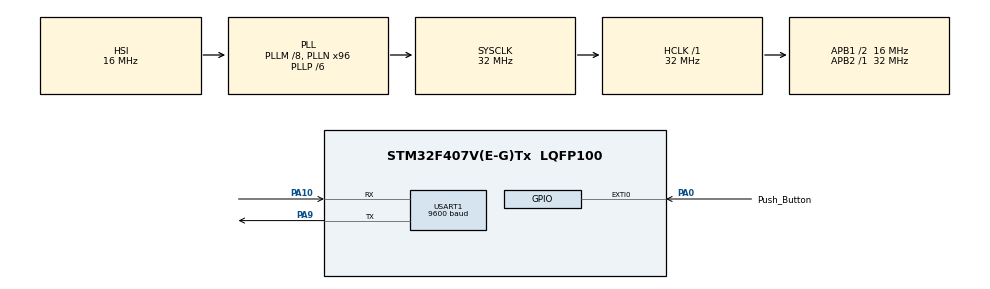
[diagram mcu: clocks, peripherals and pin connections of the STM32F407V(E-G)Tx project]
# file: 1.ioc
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Mcu.Family=STM32F4
Mcu.Name=STM32F407V(E-G)Tx
Mcu.Package=LQFP100
NVIC.EXTI0_IRQn=true\:0\:0\:false\:false\:true\:true\:true
NVIC.PriorityGroup=NVIC_PRIORITYGROUP_4
NVIC.TIM1_BRK_TIM9_IRQn=true\:0\:0\:false\:false\:true\:true\:true
NVIC.TIM1_CC_IRQn=true\:0\:0\:false\:false\:true\:true\:true
NVIC.TIM1_TRG_COM_TIM11_IRQn=true\:0\:0\:false\:false\:true\:true\:true
NVIC.TIM1_UP_TIM10_IRQn=true\:0\:0\:false\:false\:true\:true\:true
PA0-WKUP.GPIO_Label=Push_Button
PA0-WKUP.Signal=GPXTI0
PA10.Mode=Asynchronous
PA10.Signal=USART1_RX
PA9.Mode=Asynchronous
PA9.Signal=USART1_TX
ProjectManager.HeapSize=0x200
ProjectManager.StackSize=0x400
ProjectManager.TargetToolchain=TrueSTUDIO
RCC.48MHZClocksFreq_Value=48000000
RCC.AHBFreq_Value=32000000
RCC.APB1CLKDivider=RCC_HCLK_DIV2
RCC.APB1Freq_Value=16000000
RCC.APB1TimFreq_Value=32000000
RCC.APB2Freq_Value=32000000
RCC.APB2TimFreq_Value=32000000
RCC.CortexFreq_Value=32000000
RCC.HCLKFreq_Value=32000000
RCC.HSE_VALUE=25000000
RCC.HSI_VALUE=16000000
RCC.LSE_VALUE=32768
RCC.PLLM=8
RCC.PLLN=96
RCC.PLLP=RCC_PLLP_DIV6
RCC.SYSCLKFreq_VALUE=32000000
RCC.SYSCLKSource=RCC_SYSCLKSOURCE_PLLCLK
RCC.VCOOutputFreq_Value=192000000
TIM1.Period=100
TIM1.Prescaler=32000
USART1.BaudRate=9600
USART1.Mode=MODE_TX
USART1.VirtualMode=VM_ASYNC
VP_TIM1_VS_ClockSourceINT.Mode=Internal
board=custom

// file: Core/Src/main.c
/* USER CODE BEGIN Header */
/**
  ******************************************************************************
  * @file           : main.c
  * @brief          : Main program body
  ******************************************************************************
  * @attention
  *
  * <h2><center>&copy; Copyright (c) 2021 STMicroelectronics.
  * All rights reserved.</center></h2>
  *
  * This software component is licensed by ST under BSD 3-Clause license,
  * the "License"; You may not use this file except in compliance with the
  * License. You may obtain a copy of the License at:
  *                        opensource.org/licenses/BSD-3-Clause
  *
  ******************************************************************************
  */
/* USER CODE END Header */
#include "main.h"

/* USER CODE BEGIN Includes */
#include <string.h>
/* USER CODE END Includes */

TIM_HandleTypeDef htim1;

UART_HandleTypeDef huart1;

void SystemClock_Config(void);
static void MX_GPIO_Init(void);
static void MX_USART1_UART_Init(void);
static void MX_TIM1_Init(void);

int main(void)
{

  /* MCU Configuration--------------------------------------------------------*/

  /* Reset of all peripherals, Initializes the Flash interface and the Systick. */
  HAL_Init();

  /* Configure the system clock */
  SystemClock_Config();

  /* Initialize all configured peripherals */
  MX_GPIO_Init();
  MX_USART1_UART_Init();
  MX_TIM1_Init();

  /* Infinite loop */
  while (1)
  {

  }
}

void SystemClock_Config(void)
{
  RCC_OscInitTypeDef RCC_OscInitStruct = {0};
  RCC_ClkInitTypeDef RCC_ClkInitStruct = {0};

  /** Configure the main internal regulator output voltage
  */
  __HAL_RCC_PWR_CLK_ENABLE();
  __HAL_PWR_VOLTAGESCALING_CONFIG(PWR_REGULATOR_VOLTAGE_SCALE1);
  /** Initializes the RCC Oscillators according to the specified parameters
  * in the RCC_OscInitTypeDef structure.
  */
  RCC_OscInitStruct.OscillatorType = RCC_OSCILLATORTYPE_HSI;
  RCC_OscInitStruct.HSIState = RCC_HSI_ON;
  RCC_OscInitStruct.HSICalibrationValue = RCC_HSICALIBRATION_DEFAULT;
  RCC_OscInitStruct.PLL.PLLState = RCC_PLL_ON;
  RCC_OscInitStruct.PLL.PLLSource = RCC_PLLSOURCE_HSI;
  RCC_OscInitStruct.PLL.PLLM = 8;
  RCC_OscInitStruct.PLL.PLLN = 96;
  RCC_OscInitStruct.PLL.PLLP = RCC_PLLP_DIV6;
  RCC_OscInitStruct.PLL.PLLQ = 4;
  if (HAL_RCC_OscConfig(&RCC_OscInitStruct) != HAL_OK)
  {
    Error_Handler();
  }
  /** Initializes the CPU, AHB and APB buses clocks
  */
  RCC_ClkInitStruct.ClockType = RCC_CLOCKTYPE_HCLK|RCC_CLOCKTYPE_SYSCLK
                              |RCC_CLOCKTYPE_PCLK1|RCC_CLOCKTYPE_PCLK2;
  RCC_ClkInitStruct.SYSCLKSource = RCC_SYSCLKSOURCE_PLLCLK;
  RCC_ClkInitStruct.AHBCLKDivider = RCC_SYSCLK_DIV1;
  RCC_ClkInitStruct.APB1CLKDivider = RCC_HCLK_DIV2;
  RCC_ClkInitStruct.APB2CLKDivider = RCC_HCLK_DIV1;

  if (HAL_RCC_ClockConfig(&RCC_ClkInitStruct, FLASH_LATENCY_1) != HAL_OK)
  {
    Error_Handler();
  }
}

static void MX_TIM1_Init(void)
{

  TIM_ClockConfigTypeDef sClockSourceConfig = {0};
  TIM_MasterConfigTypeDef sMasterConfig = {0};

  htim1.Instance = TIM1;
  htim1.Init.Prescaler = 32000;
  htim1.Init.CounterMode = TIM_COUNTERMODE_UP;
  htim1.Init.Period = 100;
  htim1.Init.ClockDivision = TIM_CLOCKDIVISION_DIV1;
  htim1.Init.RepetitionCounter = 0;
  htim1.Init.AutoReloadPreload = TIM_AUTORELOAD_PRELOAD_DISABLE;
  if (HAL_TIM_Base_Init(&htim1) != HAL_OK)
  {
    Error_Handler();
  }
  sClockSourceConfig.ClockSource = TIM_CLOCKSOURCE_INTERNAL;
  if (HAL_TIM_ConfigClockSource(&htim1, &sClockSourceConfig) != HAL_OK)
  {
    Error_Handler();
  }
  sMasterConfig.MasterOutputTrigger = TIM_TRGO_RESET;
  sMasterConfig.MasterSlaveMode = TIM_MASTERSLAVEMODE_DISABLE;
  if (HAL_TIMEx_MasterConfigSynchronization(&htim1, &sMasterConfig) != HAL_OK)
  {
    Error_Handler();
  }

}

static void MX_USART1_UART_Init(void)
{

  huart1.Instance = USART1;
  huart1.Init.BaudRate = 9600;
  huart1.Init.WordLength = UART_WORDLENGTH_8B;
  huart1.Init.StopBits = UART_STOPBITS_1;
  huart1.Init.Parity = UART_PARITY_NONE;
  huart1.Init.Mode = UART_MODE_TX;
  huart1.Init.HwFlowCtl = UART_HWCONTROL_NONE;
  huart1.Init.OverSampling = UART_OVERSAMPLING_16;
  if (HAL_UART_Init(&huart1) != HAL_OK)
  {
    Error_Handler();
  }

}

static void MX_GPIO_Init(void)
{
  GPIO_InitTypeDef GPIO_InitStruct = {0};

  /* GPIO Ports Clock Enable */
  __HAL_RCC_GPIOA_CLK_ENABLE();

  /*Configure GPIO pin : Push_Button_Pin */
  GPIO_InitStruct.Pin = Push_Button_Pin;
  GPIO_InitStruct.Mode = GPIO_MODE_IT_RISING;
  GPIO_InitStruct.Pull = GPIO_NOPULL;
  HAL_GPIO_Init(Push_Button_GPIO_Port, &GPIO_InitStruct);

  /* EXTI interrupt init*/
  HAL_NVIC_SetPriority(EXTI0_IRQn, 0, 0);
  HAL_NVIC_EnableIRQ(EXTI0_IRQn);

}

/* USER CODE BEGIN 4 */
void HAL_GPIO_EXTI_Callback(uint16_t GPIO_Pin)
{
	TIM_HandleTypeDef *htim;
	htim = &htim1;
	if(GPIO_Pin == Push_Button_Pin && htim->State == HAL_TIM_STATE_READY){ //start timer if only button is pressed and timer is ready
		HAL_TIM_Base_Start_IT(&htim1);
	}
}

void HAL_TIM_PeriodElapsedCallback(TIM_HandleTypeDef *htim)
{
  /* Prevent unused argument(s) compilation warning */
  UNUSED(htim);

  /* NOTE : This function should not be modified, when the callback is needed,
            the HAL_TIM_PeriodElapsedCallback could be implemented in the user file
   */

  //We only need to check for unpressed button
  if(HAL_GPIO_ReadPin(Push_Button_GPIO_Port, Push_Button_Pin) == GPIO_PIN_SET){ //Button not pressed, transmit data (if > 1 s) and turn off the timer
	  if (__HAL_TIM_GET_COUNTER(htim) - 1 > 10) {// We transmit only values greater than 1s.
		  uint16_t seconds;
		  char buffer[10];
		  seconds = (uint16_t) (__HAL_TIM_GET_COUNTER(htim) - 1 )/ 10; //as timer triggers every 100 ms we should divide counter 10
		  snprintf(buffer, "%dsec\n", seconds);
		  HAL_UART_Transmit(&huart1, (uint8_t *)buffer, sizeof(buffer), 15); //We take 15ms to transmit data as for BaudRate = 9600 byte is transmitted for 1024 us. We have up to 10 bytes - its <11ms.
	  }
	  HAL_TIM_Base_Stop_IT(&htim1);
  }

}
/* USER CODE END 4 */

void Error_Handler(void)
{
  __disable_irq();
  while (1)
  {
  }
}

/************************ (C) COPYRIGHT STMicroelectronics *****END OF FILE****/
